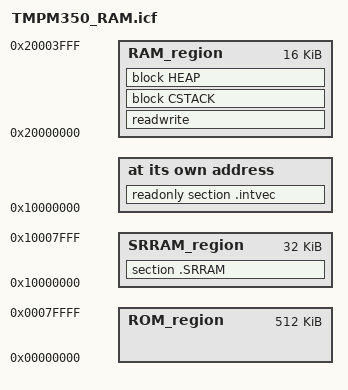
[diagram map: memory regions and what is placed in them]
/*###ICF### Section handled by ICF editor, don't touch! ****/
/*-Editor annotation file-*/
/* IcfEditorFile="$TOOLKIT_DIR$\config\ide\IcfEditor\cortex_v1_0.xml" */
/*-Specials-*/
define symbol __ICFEDIT_intvec_start__ = 0x10000000;
/*-Memory Regions-*/
define symbol __ICFEDIT_region_ROM_start__ = 0x00000000;
define symbol __ICFEDIT_region_ROM_end__   = 0x0007FFFF;
define symbol __ICFEDIT_region_RAM_start__ = 0x20000000;
define symbol __ICFEDIT_region_RAM_end__   = 0x20003FFF;
/*-Sizes-*/
define symbol __ICFEDIT_size_cstack__ = 0x200;
define symbol __ICFEDIT_size_heap__   = 0x200;
/**** End of ICF editor section. ###ICF###*/

define memory mem with size = 4G;
define region ROM_region   = mem:[from __ICFEDIT_region_ROM_start__   to __ICFEDIT_region_ROM_end__];
define region RAM_region   = mem:[from __ICFEDIT_region_RAM_start__   to __ICFEDIT_region_RAM_end__];

define symbol __region_SRRAM_start__ = 0x10000000;
define symbol __region_SRRAM_end__   = 0x10007FFF;

define region SRRAM_region  = mem:[from __region_SRRAM_start__   to __region_SRRAM_end__];

define block CSTACK    with alignment = 8, size = __ICFEDIT_size_cstack__   { };
define block HEAP      with alignment = 8, size = __ICFEDIT_size_heap__     { };

initialize by copy { readwrite };
do not initialize  { section .noinit };

place at address mem:__ICFEDIT_intvec_start__ { readonly section .intvec };

place in SRRAM_region { block app_img {readonly}};
place in RAM_region   { readwrite,
                        block CSTACK, block HEAP };
place in SRRAM_region { section .SRRAM };

define exported symbol RAM_START =    __ICFEDIT_region_RAM_start__;
define exported symbol RAM_END =      __ICFEDIT_region_RAM_end__ + 1;
define exported symbol SRRAM_START =  __region_SRRAM_start__;
define exported symbol SRRAM_END =    __region_SRRAM_end__ + 1;
